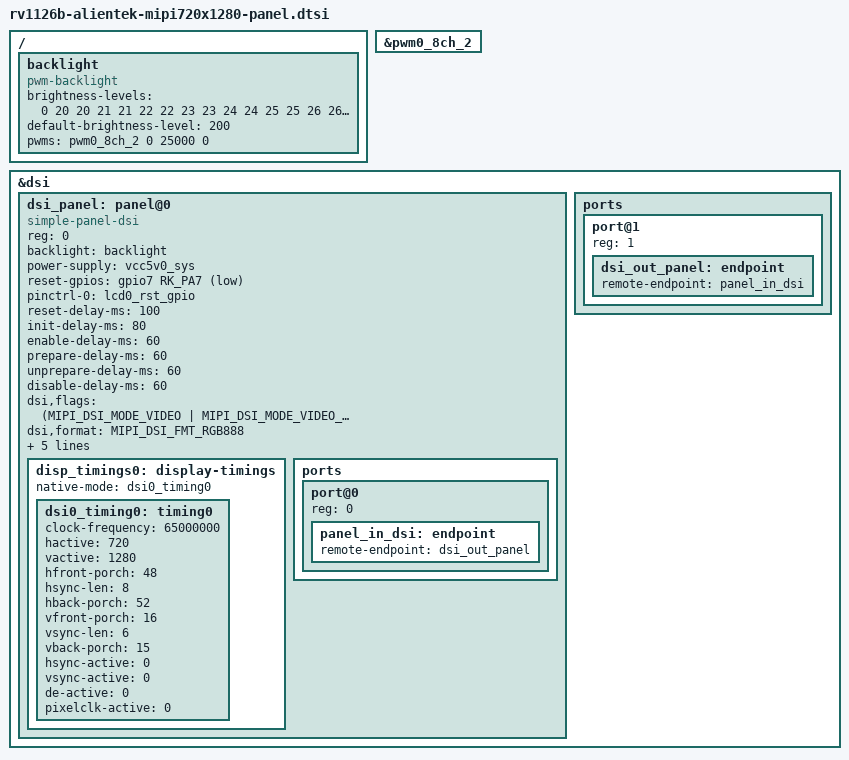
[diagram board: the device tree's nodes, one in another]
// SPDX-License-Identifier: (GPL-2.0+ OR MIT)
/*
 * Copyright (c) 2025 Rockchip Electronics Co., Ltd.
 *
 * Reusable 720x1280 MIPI-DSI panel configuration.
 */

/ {
	backlight: backlight {
		compatible = "pwm-backlight";
		brightness-levels = <
			  0  20  20  21  21  22  22  23
			 23  24  24  25  25  26  26  27
			 27  28  28  29  29  30  30  31
			 31  32  32  33  33  34  34  35
			 35  36  36  37  37  38  38  39
			 40  41  42  43  44  45  46  47
			 48  49  50  51  52  53  54  55
			 56  57  58  59  60  61  62  63
			 64  65  66  67  68  69  70  71
			 72  73  74  75  76  77  78  79
			 80  81  82  83  84  85  86  87
			 88  89  90  91  92  93  94  95
			 96  97  98  99 100 101 102 103
			104 105 106 107 108 109 110 111
			112 113 114 115 116 117 118 119
			120 121 122 123 124 125 126 127
			128 129 130 131 132 133 134 135
			136 137 138 139 140 141 142 143
			144 145 146 147 148 149 150 151
			152 153 154 155 156 157 158 159
			160 161 162 163 164 165 166 167
			168 169 170 171 172 173 174 175
			176 177 178 179 180 181 182 183
			184 185 186 187 188 189 190 191
			192 193 194 195 196 197 198 199
			200 201 202 203 204 205 206 207
			208 209 210 211 212 213 214 215
			216 217 218 219 220 221 222 223
			224 225 226 227 228 229 230 231
			232 233 234 235 236 237 238 239
			240 241 242 243 244 245 246 247
			248 249 250 251 252 253 254 255
		>;
		default-brightness-level = <200>;
	};
};

&pwm0_8ch_2 {
	status = "okay";
};

&backlight {
	pwms = <&pwm0_8ch_2 0 25000 0>;
	status = "okay";
};

&dsi {
	status = "okay";
	/* rockchip,lane-rate = <1000>; */

	dsi_panel: panel@0 {
		compatible = "simple-panel-dsi";
		reg = <0>;
		backlight = <&backlight>;
		power-supply = <&vcc5v0_sys>;
		reset-gpios = <&gpio7 RK_PA7 GPIO_ACTIVE_LOW>;
		pinctrl-names = "default";
		pinctrl-0 = <&lcd0_rst_gpio>;
		reset-delay-ms = <100>;
		init-delay-ms = <80>;
		enable-delay-ms = <60>;
		prepare-delay-ms = <60>;
		unprepare-delay-ms = <60>;
		disable-delay-ms = <60>;
		dsi,flags = <(MIPI_DSI_MODE_VIDEO | MIPI_DSI_MODE_VIDEO_BURST |
			MIPI_DSI_MODE_LPM | MIPI_DSI_MODE_NO_EOT_PACKET)>;
		dsi,format = <MIPI_DSI_FMT_RGB888>;
		dsi,lanes = <4>;
		status = "okay";

		panel-init-sequence = [
			39 00 04 B9 FF 83 94
			39 00 07 BA 63 03 68 6B B2 C0
			/* 15 00 02 36 01: reverse orientation */
			/* 15 00 02 36 02: normal orientation */
			15 00 02 36 01
			39 00 0B B1 48 12 72 09 32 54 71 71 57 47
			39 00 07 B2 00 80 64 0C 0D 2F
			39 00 16 B4 73 74 73 74 73 74 01 0C 86 75 00 3F 73 74 73 74 73 74 01 0C 86
			39 00 03 B6 6E 6E
			39 00 22 D3 00 00 07 07 40 07 0C 00 08 10 08 00 08 54 15 0A 05 0A 02 15 06 05 06 47 44 0A 0A 4B 10 07 07 0C 40
			39 00 2D D5 1C 1C 1D 1D 00 01 02 03 04 05 06 07 08 09 0A 0B 24 25 18 18 26 27 18 18 18 18 18 18 18 18 18 18 18 18 18 18 18 18 20 21 18 18 18 18
			39 00 2D D6 1C 1C 1D 1D 07 06 05 04 03 02 01 00 0B 0A 09 08 21 20 18 18 27 26 18 18 18 18 18 18 18 18 18 18 18 18 18 18 18 18 25 24 18 18 18 18
			39 00 3B E0 00 0A 15 1B 1E 21 24 22 47 56 65 66 6E 82 88 8B 9A 9D 98 A8 B9 5D 5C 61 66 6A 6F 7F 7F 00 0A 15 1B 1E 21 24 22 47 56 65 65 6E 81 87 8B 98 9D 99 A8 BA 5D 5D 62 67 6B 72 7F 7F
			39 00 03 C0 1F 31
			15 00 02 CC 03
			15 00 02 D4 02
			15 00 02 BD 02
			39 00 0D D8 FF FF FF FF FF FF FF FF FF FF FF FF
			15 00 02 BD 00
			15 00 02 BD 01
			15 00 02 B1 00
			15 00 02 BD 00
			39 00 08 BF 40 81 50 00 1A FC 01
			15 00 02 C6 ED
			05 64 01 11
			05 78 01 29
		];

		panel-exit-sequence = [
			05 32 01 28
			05 C8 01 10
		];

		disp_timings0: display-timings {
			native-mode = <&dsi0_timing0>;
			dsi0_timing0: timing0 {
				clock-frequency = <65000000>;
				hactive = <720>;
				vactive = <1280>;
				hfront-porch = <48>;
				hsync-len = <8>;
				hback-porch = <52>;
				vfront-porch = <16>;
				vsync-len = <6>;
				vback-porch = <15>;
				hsync-active = <0>;
				vsync-active = <0>;
				de-active = <0>;
				pixelclk-active = <0>;
			};
		};

		ports {
			#address-cells = <1>;
			#size-cells = <0>;

			port@0 {
				reg = <0>;
				panel_in_dsi: endpoint {
					remote-endpoint = <&dsi_out_panel>;
				};
			};
		};
	};

	ports {
		#address-cells = <1>;
		#size-cells = <0>;

		port@1 {
			reg = <1>;
			dsi_out_panel: endpoint {
				remote-endpoint = <&panel_in_dsi>;
			};
		};
	};
};
